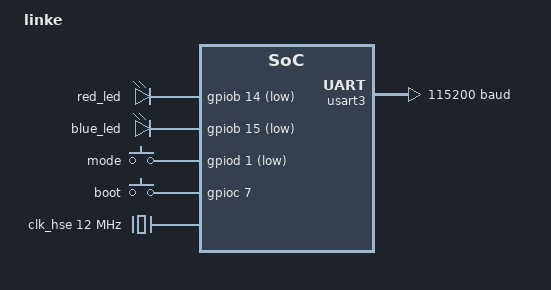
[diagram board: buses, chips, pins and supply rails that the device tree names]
/*
 * Copyright (c) 2024 MASSDRIVER EI (massdriver.space)
 * SPDX-License-Identifier: Apache-2.0
 */

/dts-v1/;

#include <wch/ch32v305/ch32v305fbp.dtsi>
#include <zephyr/dt-bindings/gpio/gpio.h>
#include <zephyr/dt-bindings/input/input-event-codes.h>
#include "linke-pinctrl.dtsi"

/ {
	model = "linke";
	compatible = "wch,ch32v305";

	chosen {
		zephyr,sram = &sram0;
		zephyr,flash = &flash0;
		zephyr,console = &usart3;
		zephyr,shell-uart = &usart3;
	};

	leds {
		compatible = "gpio-leds";
		status = "okay";

		red_led: led0 {
			gpios = <&gpiob 14 GPIO_ACTIVE_LOW>;
		};

		blue_led: led1 {
			gpios = <&gpiob 15 GPIO_ACTIVE_LOW>;
		};
	};

	buttons {
		compatible = "gpio-keys";

		mode: sw0 {
			gpios = <&gpiod 1 GPIO_ACTIVE_LOW>;
			zephyr,code = <INPUT_KEY_0>;
		};

		boot: sw1 {
			gpios = <&gpioc 7 GPIO_ACTIVE_HIGH>;
			zephyr,code = <INPUT_KEY_1>;
		};
	};

	aliases {
		led0 = &blue_led;
		sw0 = &mode;
	};
};

&clk_hse {
	clock-frequency = <DT_FREQ_M(12)>;
	status = "okay";
};

&pll {
	clocks = <&clk_hse>;
	status = "okay";
};

&rcc {
	clocks = <&pll>;
};

&gpioa {
	status = "okay";
};

&gpioc {
	status = "okay";
};

&usart3 {
	status = "okay";
	current-speed = <115200>;
	pinctrl-0 = <&usart3_default>;
	pinctrl-names = "default";
};
